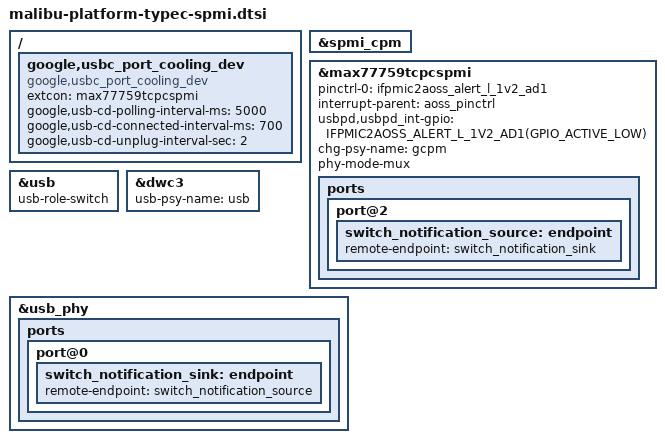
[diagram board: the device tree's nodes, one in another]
// SPDX-License-Identifier: GPL-2.0-only
/*
 * Google Spacecraft USB.Type-C.spmi.device source
 *
 * Copyright 2025-2026 Google LLC.
 *
 */
#include <dt-bindings/usb/pd.h>
#include <dt-bindings/gpio/gpio.h>
#include <dt-bindings/gpio/google,mbu.h>

&spmi_cpm {
	status = "okay";
	#address-cells = <1>;
	#size-cells = <1>;

#include "max777x9-tcpc-spmi.dtsi"
};

&max77759tcpcspmi {
	status = "okay";
	pinctrl-names = "default";
	pinctrl-0 = <&ifpmic2aoss_alert_l_1v2_ad1>;
	interrupt-parent = <&aoss_pinctrl>;
	usbpd,usbpd_int-gpio = <IFPMIC2AOSS_ALERT_L_1V2_AD1(GPIO_ACTIVE_LOW)>;
	chg-psy-name = "gcpm";
	phy-mode-mux;

	ports {
		port@2 {
			switch_notification_source: endpoint {
				remote-endpoint = <&switch_notification_sink>;
			};
		};
	};
};

&usb {
	usb-role-switch;
};

&dwc3 {
	usb-psy-name = "usb";
};

&usb_phy {
	ports {
		port@0 {
			switch_notification_sink: endpoint {
				remote-endpoint = <&switch_notification_source>;
			};
		};
	};
};

/ {
	fragment@typec {
		target-path = "/";
		__overlay__ {
			google,usbc_port_cooling_dev {
				extcon = <&max77759tcpcspmi>;
				compatible = "google,usbc_port_cooling_dev";
				google,usb-cd-polling-interval-ms = <5000>;
				google,usb-cd-connected-interval-ms = <700>;
				google,usb-cd-unplug-interval-sec = <2>;
				#cooling-cells = <2>;
			};
		};
	};
};
